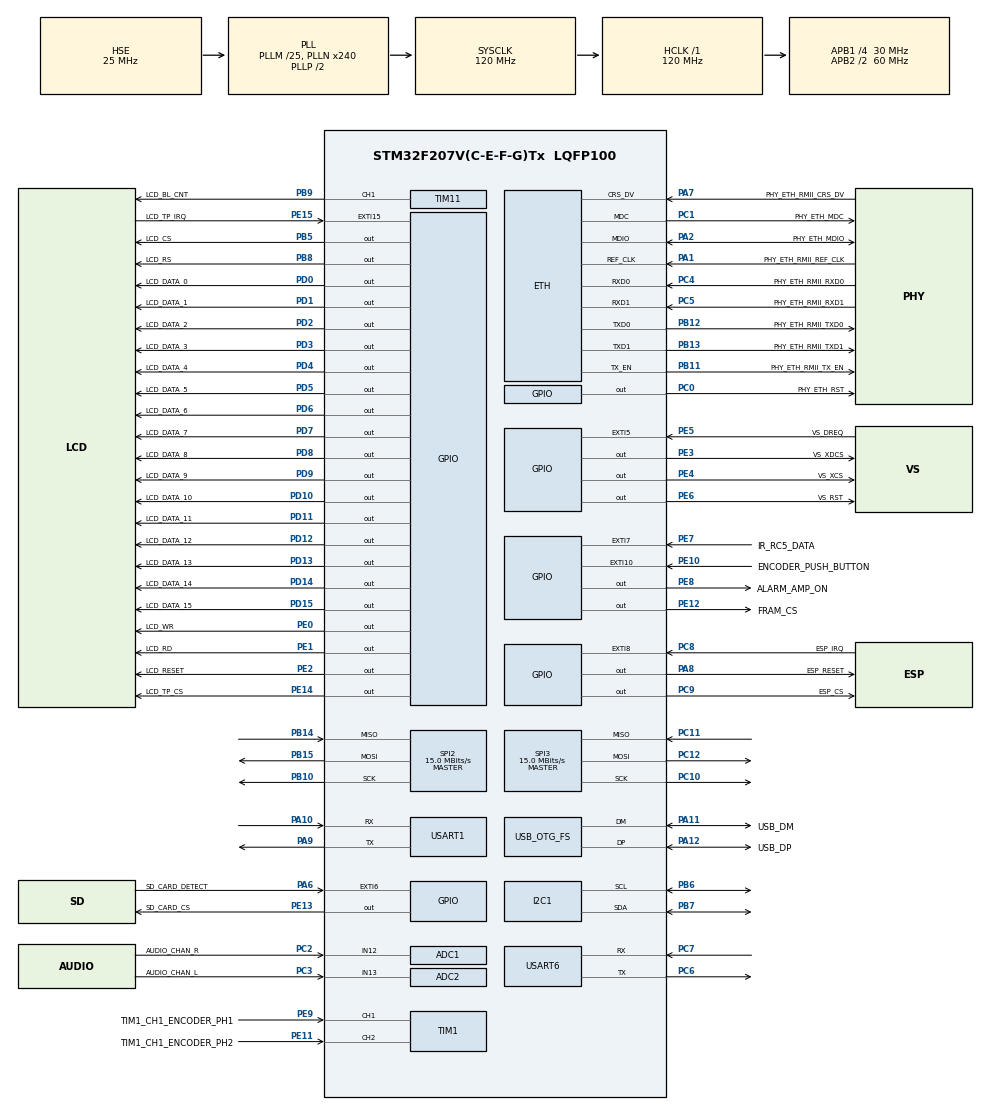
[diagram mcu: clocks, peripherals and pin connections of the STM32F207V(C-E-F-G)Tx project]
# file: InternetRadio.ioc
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ADC1.Channel-0\#ChannelRegularConversion=ADC_CHANNEL_12
ADC1.ClockPrescaler=ADC_CLOCK_SYNC_PCLK_DIV4
ADC1.NbrOfConversionFlag=1
ADC1.Rank-0\#ChannelRegularConversion=1
ADC1.SamplingTime-0\#ChannelRegularConversion=ADC_SAMPLETIME_3CYCLES
ADC1.master=1
ADC2.Channel-0\#ChannelRegularConversion=ADC_CHANNEL_13
ADC2.ClockPrescaler=ADC_CLOCK_SYNC_PCLK_DIV4
ADC2.NbrOfConversionFlag=1
ADC2.Rank-0\#ChannelRegularConversion=1
ADC2.SamplingTime-0\#ChannelRegularConversion=ADC_SAMPLETIME_3CYCLES
ETH.MediaInterface=ETH_MEDIA_INTERFACE_RMII
ETH.PHY_Name_RMII=DP83848_PHY_ADDRESS
FATFS._USE_FIND=1
FREERTOS.Tasks01=defaultTask,24,128,StartDefaultTask,Default,NULL,Dynamic,NULL,NULL
FREERTOS.configUSE_NEWLIB_REENTRANT=1
LWIP.Version=v2.0.3_Cube
Mcu.Family=STM32F2
Mcu.Name=STM32F207V(C-E-F-G)Tx
Mcu.Package=LQFP100
NVIC.ETH_IRQn=true\:5\:0\:false\:false\:true\:true\:false\:true
NVIC.PriorityGroup=NVIC_PRIORITYGROUP_4
PA0-WKUP.GPIO_Label=PHY_ETH_INT
PA0-WKUP.Mode=SYS_WakeUp0
PA0-WKUP.Signal=SYS_WKUP
PA1.GPIO_Label=PHY_ETH_RMII_REF_CLK
PA1.Mode=RMII
PA1.Signal=ETH_REF_CLK
PA10.Mode=Asynchronous
PA10.Signal=USART1_RX
PA11.GPIO_Label=USB_DM
PA11.Mode=Device_Only
PA11.Signal=USB_OTG_FS_DM
PA12.GPIO_Label=USB_DP
PA12.Mode=Device_Only
PA12.Signal=USB_OTG_FS_DP
PA13.GPIO_Label=JTMS
PA13.Mode=JTAG_5_pins
PA13.Signal=SYS_JTMS-SWDIO
PA14.GPIO_Label=JTCK
PA14.Mode=JTAG_5_pins
PA14.Signal=SYS_JTCK-SWCLK
PA15.GPIO_Label=JTDI
PA15.Mode=JTAG_5_pins
PA15.Signal=SYS_JTDI
PA2.GPIO_Label=PHY_ETH_MDIO
PA2.Mode=RMII
PA2.Signal=ETH_MDIO
PA6.GPIO_Label=SD_CARD_DETECT
PA6.Signal=GPXTI6
PA7.GPIO_Label=PHY_ETH_RMII_CRS_DV
PA7.Mode=RMII
PA7.Signal=ETH_CRS_DV
PA8.GPIO_Label=ESP_RESET
PA8.Signal=GPIO_Output
PA9.Mode=Asynchronous
PA9.Signal=USART1_TX
PB10.Mode=Full_Duplex_Master
PB10.Signal=SPI2_SCK
PB11.GPIO_Label=PHY_ETH_RMII_TX_EN
PB11.Mode=RMII
PB11.Signal=ETH_TX_EN
PB12.GPIO_Label=PHY_ETH_RMII_TXD0
PB12.Mode=RMII
PB12.Signal=ETH_TXD0
PB13.GPIO_Label=PHY_ETH_RMII_TXD1
PB13.Mode=RMII
PB13.Signal=ETH_TXD1
PB14.Mode=Full_Duplex_Master
PB14.Signal=SPI2_MISO
PB15.Mode=Full_Duplex_Master
PB15.Signal=SPI2_MOSI
PB3.GPIO_Label=JTDO
PB3.Mode=JTAG_5_pins
PB3.Signal=SYS_JTDO-SWO
PB4.GPIO_Label=JTRST
PB4.Mode=JTAG_5_pins
PB4.Signal=SYS_JTRST
PB5.GPIO_Label=LCD_CS
PB5.Signal=GPIO_Output
PB6.Mode=I2C
PB6.Signal=I2C1_SCL
PB7.Mode=I2C
PB7.Signal=I2C1_SDA
PB8.GPIO_Label=LCD_RS
PB8.Signal=GPIO_Output
PB9.GPIO_Label=LCD_BL_CNT
PB9.Signal=S_TIM11_CH1
PC0.GPIO_Label=PHY_ETH_RST
PC0.Signal=GPIO_Output
PC1.GPIO_Label=PHY_ETH_MDC
PC1.Mode=RMII
PC1.Signal=ETH_MDC
PC10.Mode=Full_Duplex_Master
PC10.Signal=SPI3_SCK
PC11.Mode=Full_Duplex_Master
PC11.Signal=SPI3_MISO
PC12.Mode=Full_Duplex_Master
PC12.Signal=SPI3_MOSI
PC14-OSC32_IN.Mode=LSE-External-Oscillator
PC14-OSC32_IN.Signal=RCC_OSC32_IN
PC15-OSC32_OUT.Mode=LSE-External-Oscillator
PC15-OSC32_OUT.Signal=RCC_OSC32_OUT
PC2.GPIO_Label=AUDIO_CHAN_R
PC2.Signal=ADCx_IN12
PC3.GPIO_Label=AUDIO_CHAN_L
PC3.Signal=ADCx_IN13
PC4.GPIO_Label=PHY_ETH_RMII_RXD0
PC4.Mode=RMII
PC4.Signal=ETH_RXD0
PC5.GPIO_Label=PHY_ETH_RMII_RXD1
PC5.Mode=RMII
PC5.Signal=ETH_RXD1
PC6.Mode=Asynchronous
PC6.Signal=USART6_TX
PC7.Mode=Asynchronous
PC7.Signal=USART6_RX
PC8.GPIO_Label=ESP_IRQ
PC8.Signal=GPXTI8
PC9.GPIO_Label=ESP_CS
PC9.Signal=GPIO_Output
PD0.GPIO_Label=LCD_DATA_0
PD0.Signal=GPIO_Output
PD1.GPIO_Label=LCD_DATA_1
PD1.Signal=GPIO_Output
PD10.GPIO_Label=LCD_DATA_10
PD10.Signal=GPIO_Output
PD11.GPIO_Label=LCD_DATA_11
PD11.Signal=GPIO_Output
PD12.GPIO_Label=LCD_DATA_12
PD12.Signal=GPIO_Output
PD13.GPIO_Label=LCD_DATA_13
PD13.Signal=GPIO_Output
PD14.GPIO_Label=LCD_DATA_14
PD14.Signal=GPIO_Output
PD15.GPIO_Label=LCD_DATA_15
PD15.Signal=GPIO_Output
PD2.GPIO_Label=LCD_DATA_2
PD2.Signal=GPIO_Output
PD3.GPIO_Label=LCD_DATA_3
PD3.Signal=GPIO_Output
PD4.GPIO_Label=LCD_DATA_4
PD4.Signal=GPIO_Output
PD5.GPIO_Label=LCD_DATA_5
PD5.Signal=GPIO_Output
PD6.GPIO_Label=LCD_DATA_6
PD6.Signal=GPIO_Output
PD7.GPIO_Label=LCD_DATA_7
PD7.Signal=GPIO_Output
PD8.GPIO_Label=LCD_DATA_8
PD8.Signal=GPIO_Output
PD9.GPIO_Label=LCD_DATA_9
PD9.Signal=GPIO_Output
PE0.GPIO_Label=LCD_WR
PE0.Signal=GPIO_Output
PE1.GPIO_Label=LCD_RD
PE1.Signal=GPIO_Output
PE10.GPIO_Label=ENCODER_PUSH_BUTTON
PE10.Signal=GPXTI10
PE11.GPIO_Label=TIM1_CH1_ENCODER_PH2
PE11.Signal=S_TIM1_CH2
PE12.GPIO_Label=FRAM_CS
PE12.Signal=GPIO_Output
PE13.GPIO_Label=SD_CARD_CS
PE13.Signal=GPIO_Output
PE14.GPIO_Label=LCD_TP_CS
PE14.Signal=GPIO_Output
PE15.GPIO_Label=LCD_TP_IRQ
PE15.Signal=GPXTI15
PE2.GPIO_Label=LCD_RESET
PE2.Signal=GPIO_Output
PE3.GPIO_Label=VS_XDCS
PE3.Signal=GPIO_Output
PE4.GPIO_Label=VS_XCS
PE4.Signal=GPIO_Output
PE5.GPIO_Label=VS_DREQ
PE5.Signal=GPXTI5
PE6.GPIO_Label=VS_RST
PE6.Signal=GPIO_Output
PE7.GPIO_Label=IR_RC5_DATA
PE7.Signal=GPXTI7
PE8.GPIO_Label=ALARM_AMP_ON
PE8.Signal=GPIO_Output
PE9.GPIO_Label=TIM1_CH1_ENCODER_PH1
PE9.Signal=S_TIM1_CH1
PH0-OSC_IN.Mode=HSE-External-Oscillator
PH0-OSC_IN.Signal=RCC_OSC_IN
PH1-OSC_OUT.Mode=HSE-External-Oscillator
PH1-OSC_OUT.Signal=RCC_OSC_OUT
ProjectManager.HeapSize=0x200
ProjectManager.StackSize=0x400
ProjectManager.TargetToolchain=STM32CubeIDE
RCC.48MHZClocksFreq_Value=48000000
RCC.AHBFreq_Value=120000000
RCC.APB1CLKDivider=RCC_HCLK_DIV4
RCC.APB1Freq_Value=30000000
RCC.APB1TimFreq_Value=60000000
RCC.APB2CLKDivider=RCC_HCLK_DIV2
RCC.APB2Freq_Value=60000000
RCC.APB2TimFreq_Value=120000000
RCC.CortexFreq_Value=120000000
RCC.HCLKFreq_Value=120000000
RCC.HSE_VALUE=25000000
RCC.HSI_VALUE=16000000
RCC.PLLM=25
RCC.PLLN=240
RCC.PLLQ=5
RCC.PLLSourceVirtual=RCC_PLLSOURCE_HSE
RCC.RCC_RTC_Clock_Source=RCC_RTCCLKSOURCE_LSE
RCC.RCC_RTC_Clock_SourceVirtual=RCC_RTCCLKSOURCE_LSE
RCC.SYSCLKFreq_VALUE=120000000
RCC.SYSCLKSource=RCC_SYSCLKSOURCE_PLLCLK
RCC.VCOOutputFreq_Value=240000000
SH.ADCx_IN12.0=ADC1_IN12,IN12
SH.ADCx_IN13.0=ADC2_IN13,IN13
SH.S_TIM11_CH1.0=TIM11_CH1,PWM Generation1 CH1
SH.S_TIM1_CH1.0=TIM1_CH1,Encoder_Interface
SH.S_TIM1_CH2.0=TIM1_CH2,Encoder_Interface
SPI2.BaudRatePrescaler=SPI_BAUDRATEPRESCALER_2
SPI2.CalculateBaudRate=15.0 MBits/s
SPI2.Direction=SPI_DIRECTION_2LINES
SPI2.Mode=SPI_MODE_MASTER
SPI2.VirtualType=VM_MASTER
SPI3.BaudRatePrescaler=SPI_BAUDRATEPRESCALER_2
SPI3.CalculateBaudRate=15.0 MBits/s
SPI3.Direction=SPI_DIRECTION_2LINES
SPI3.Mode=SPI_MODE_MASTER
SPI3.VirtualType=VM_MASTER
TIM11.Channel=TIM_CHANNEL_1
TIM11.Period=0x0064
TIM11.Prescaler=0x0075
TIM7.Prescaler=0x001D
USART1.VirtualMode=VM_ASYNC
USART6.VirtualMode=VM_ASYNC
USB_OTG_FS.VirtualMode=Device_Only
VP_FATFS_VS_Generic.Mode=User_defined
VP_FREERTOS_VS_CMSIS_V2.Mode=CMSIS_V2
VP_LWIP_VS_Enabled.Mode=Enabled
VP_RTC_VS_RTC_Activate.Mode=RTC_Enabled
VP_RTC_VS_RTC_Calendar.Mode=RTC_Calendar
VP_TIM11_VS_ClockSourceINT.Mode=Enable_Timer
VP_TIM7_VS_ClockSourceINT.Mode=Enable_Timer
board=custom

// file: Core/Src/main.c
/* USER CODE BEGIN Header */
/**
  ******************************************************************************
  * @file           : main.c
  * @brief          : Main program body
  ******************************************************************************
  * @attention
  *
  * Copyright (c) 2021 STMicroelectronics.
  * All rights reserved.
  *
  * This software is licensed under terms that can be found in the LICENSE file
  * in the root directory of this software component.
  * If no LICENSE file comes with this software, it is provided AS-IS.
  *
  ******************************************************************************
  */
/* USER CODE END Header */
#include "main.h"
#include "cmsis_os.h"
#include "fatfs.h"
#include "lwip.h"

ADC_HandleTypeDef hadc1;
ADC_HandleTypeDef hadc2;

I2C_HandleTypeDef hi2c1;

RTC_HandleTypeDef hrtc;

SPI_HandleTypeDef hspi2;
SPI_HandleTypeDef hspi3;

TIM_HandleTypeDef htim1;
TIM_HandleTypeDef htim7;
TIM_HandleTypeDef htim11;

UART_HandleTypeDef huart1;
UART_HandleTypeDef huart6;

PCD_HandleTypeDef hpcd_USB_OTG_FS;

/* Definitions for defaultTask */
osThreadId_t defaultTaskHandle;
const osThreadAttr_t defaultTask_attributes = {
  .name = "defaultTask",
  .stack_size = 128 * 4,
  .priority = (osPriority_t) osPriorityNormal,
};
/* USER CODE BEGIN PV */
osThreadId_t LED_HB_Task_handle;
const osThreadAttr_t LED_HB_Task_attributes = {
  .name = "LED_HB_Task",
  .stack_size = 128 * 4,
  .priority = (osPriority_t) osPriorityNormal,
};
/* USER CODE END PV */

void SystemClock_Config(void);
static void MX_GPIO_Init(void);
static void MX_ADC1_Init(void);
static void MX_ADC2_Init(void);
static void MX_I2C1_Init(void);
static void MX_SPI2_Init(void);
static void MX_SPI3_Init(void);
static void MX_TIM1_Init(void);
static void MX_USART1_UART_Init(void);
static void MX_USART6_UART_Init(void);
static void MX_USB_OTG_FS_PCD_Init(void);
static void MX_RTC_Init(void);
static void MX_TIM7_Init(void);
static void MX_TIM11_Init(void);
void StartDefaultTask(void *argument);

/* USER CODE BEGIN PFP */
void LED_HB_Task(void *argument);
/* USER CODE END PFP */

int main(void)
{

  /* MCU Configuration--------------------------------------------------------*/

  /* Reset of all peripherals, Initializes the Flash interface and the Systick. */
  HAL_Init();

  /* Configure the system clock */
  SystemClock_Config();

  /* Initialize all configured peripherals */
  MX_GPIO_Init();
  MX_ADC1_Init();
  MX_ADC2_Init();
  MX_I2C1_Init();
  MX_SPI2_Init();
  MX_SPI3_Init();
  MX_TIM1_Init();
  MX_USART1_UART_Init();
  MX_USART6_UART_Init();
  MX_USB_OTG_FS_PCD_Init();
  MX_FATFS_Init();
  MX_RTC_Init();
  MX_TIM7_Init();
  MX_TIM11_Init();

  /* Init scheduler */
  osKernelInitialize();

  /* Create the thread(s) */
  /* creation of defaultTask */
  defaultTaskHandle = osThreadNew(StartDefaultTask, NULL, &defaultTask_attributes);

  /* USER CODE BEGIN RTOS_THREADS */
  LED_HB_Task_handle = osThreadNew(LED_HB_Task, NULL, &LED_HB_Task_attributes);
  /* add threads, ... */
  /* USER CODE END RTOS_THREADS */

  /* Start scheduler */
  osKernelStart();

  /* We should never get here as control is now taken by the scheduler */
  /* Infinite loop */
  while (1)
  {

  }
}

void SystemClock_Config(void)
{
  RCC_OscInitTypeDef RCC_OscInitStruct = {0};
  RCC_ClkInitTypeDef RCC_ClkInitStruct = {0};
  RCC_PeriphCLKInitTypeDef PeriphClkInitStruct = {0};

  /** Initializes the RCC Oscillators according to the specified parameters
  * in the RCC_OscInitTypeDef structure.
  */
  RCC_OscInitStruct.OscillatorType = RCC_OSCILLATORTYPE_HSE|RCC_OSCILLATORTYPE_LSE;
  RCC_OscInitStruct.HSEState = RCC_HSE_ON;
  RCC_OscInitStruct.LSEState = RCC_LSE_ON;
  RCC_OscInitStruct.PLL.PLLState = RCC_PLL_ON;
  RCC_OscInitStruct.PLL.PLLSource = RCC_PLLSOURCE_HSE;
  RCC_OscInitStruct.PLL.PLLM = 25;
  RCC_OscInitStruct.PLL.PLLN = 240;
  RCC_OscInitStruct.PLL.PLLP = RCC_PLLP_DIV2;
  RCC_OscInitStruct.PLL.PLLQ = 5;
  if (HAL_RCC_OscConfig(&RCC_OscInitStruct) != HAL_OK)
  {
    Error_Handler();
  }
  /** Initializes the CPU, AHB and APB buses clocks
  */
  RCC_ClkInitStruct.ClockType = RCC_CLOCKTYPE_HCLK|RCC_CLOCKTYPE_SYSCLK
                              |RCC_CLOCKTYPE_PCLK1|RCC_CLOCKTYPE_PCLK2;
  RCC_ClkInitStruct.SYSCLKSource = RCC_SYSCLKSOURCE_PLLCLK;
  RCC_ClkInitStruct.AHBCLKDivider = RCC_SYSCLK_DIV1;
  RCC_ClkInitStruct.APB1CLKDivider = RCC_HCLK_DIV4;
  RCC_ClkInitStruct.APB2CLKDivider = RCC_HCLK_DIV2;

  if (HAL_RCC_ClockConfig(&RCC_ClkInitStruct, FLASH_LATENCY_3) != HAL_OK)
  {
    Error_Handler();
  }
  PeriphClkInitStruct.PeriphClockSelection = RCC_PERIPHCLK_RTC;
  PeriphClkInitStruct.RTCClockSelection = RCC_RTCCLKSOURCE_LSE;
  if (HAL_RCCEx_PeriphCLKConfig(&PeriphClkInitStruct) != HAL_OK)
  {
    Error_Handler();
  }
}

static void MX_ADC1_Init(void)
{

  ADC_ChannelConfTypeDef sConfig = {0};

  /** Configure the global features of the ADC (Clock, Resolution, Data Alignment and number of conversion)
  */
  hadc1.Instance = ADC1;
  hadc1.Init.ClockPrescaler = ADC_CLOCK_SYNC_PCLK_DIV4;
  hadc1.Init.Resolution = ADC_RESOLUTION_12B;
  hadc1.Init.ScanConvMode = DISABLE;
  hadc1.Init.ContinuousConvMode = DISABLE;
  hadc1.Init.DiscontinuousConvMode = DISABLE;
  hadc1.Init.ExternalTrigConvEdge = ADC_EXTERNALTRIGCONVEDGE_NONE;
  hadc1.Init.ExternalTrigConv = ADC_SOFTWARE_START;
  hadc1.Init.DataAlign = ADC_DATAALIGN_RIGHT;
  hadc1.Init.NbrOfConversion = 1;
  hadc1.Init.DMAContinuousRequests = DISABLE;
  hadc1.Init.EOCSelection = ADC_EOC_SINGLE_CONV;
  if (HAL_ADC_Init(&hadc1) != HAL_OK)
  {
    Error_Handler();
  }
  /** Configure for the selected ADC regular channel its corresponding rank in the sequencer and its sample time.
  */
  sConfig.Channel = ADC_CHANNEL_12;
  sConfig.Rank = 1;
  sConfig.SamplingTime = ADC_SAMPLETIME_3CYCLES;
  if (HAL_ADC_ConfigChannel(&hadc1, &sConfig) != HAL_OK)
  {
    Error_Handler();
  }

}

static void MX_ADC2_Init(void)
{

  ADC_ChannelConfTypeDef sConfig = {0};

  /** Configure the global features of the ADC (Clock, Resolution, Data Alignment and number of conversion)
  */
  hadc2.Instance = ADC2;
  hadc2.Init.ClockPrescaler = ADC_CLOCK_SYNC_PCLK_DIV4;
  hadc2.Init.Resolution = ADC_RESOLUTION_12B;
  hadc2.Init.ScanConvMode = DISABLE;
  hadc2.Init.ContinuousConvMode = DISABLE;
  hadc2.Init.DiscontinuousConvMode = DISABLE;
  hadc2.Init.ExternalTrigConvEdge = ADC_EXTERNALTRIGCONVEDGE_NONE;
  hadc2.Init.ExternalTrigConv = ADC_SOFTWARE_START;
  hadc2.Init.DataAlign = ADC_DATAALIGN_RIGHT;
  hadc2.Init.NbrOfConversion = 1;
  hadc2.Init.DMAContinuousRequests = DISABLE;
  hadc2.Init.EOCSelection = ADC_EOC_SINGLE_CONV;
  if (HAL_ADC_Init(&hadc2) != HAL_OK)
  {
    Error_Handler();
  }
  /** Configure for the selected ADC regular channel its corresponding rank in the sequencer and its sample time.
  */
  sConfig.Channel = ADC_CHANNEL_13;
  sConfig.Rank = 1;
  sConfig.SamplingTime = ADC_SAMPLETIME_3CYCLES;
  if (HAL_ADC_ConfigChannel(&hadc2, &sConfig) != HAL_OK)
  {
    Error_Handler();
  }

}

static void MX_I2C1_Init(void)
{

  hi2c1.Instance = I2C1;
  hi2c1.Init.ClockSpeed = 100000;
  hi2c1.Init.DutyCycle = I2C_DUTYCYCLE_2;
  hi2c1.Init.OwnAddress1 = 0;
  hi2c1.Init.AddressingMode = I2C_ADDRESSINGMODE_7BIT;
  hi2c1.Init.DualAddressMode = I2C_DUALADDRESS_DISABLE;
  hi2c1.Init.OwnAddress2 = 0;
  hi2c1.Init.GeneralCallMode = I2C_GENERALCALL_DISABLE;
  hi2c1.Init.NoStretchMode = I2C_NOSTRETCH_DISABLE;
  if (HAL_I2C_Init(&hi2c1) != HAL_OK)
  {
    Error_Handler();
  }

}

static void MX_RTC_Init(void)
{

  RTC_TimeTypeDef sTime = {0};
  RTC_DateTypeDef sDate = {0};

  /** Initialize RTC Only
  */
  hrtc.Instance = RTC;
  hrtc.Init.HourFormat = RTC_HOURFORMAT_24;
  hrtc.Init.AsynchPrediv = 127;
  hrtc.Init.SynchPrediv = 255;
  hrtc.Init.OutPut = RTC_OUTPUT_DISABLE;
  hrtc.Init.OutPutPolarity = RTC_OUTPUT_POLARITY_HIGH;
  hrtc.Init.OutPutType = RTC_OUTPUT_TYPE_OPENDRAIN;
  if (HAL_RTC_Init(&hrtc) != HAL_OK)
  {
    Error_Handler();
  }

  /** Initialize RTC and set the Time and Date
  */
  sTime.Hours = 0x0;
  sTime.Minutes = 0x0;
  sTime.Seconds = 0x0;
  sTime.DayLightSaving = RTC_DAYLIGHTSAVING_NONE;
  sTime.StoreOperation = RTC_STOREOPERATION_RESET;
  if (HAL_RTC_SetTime(&hrtc, &sTime, RTC_FORMAT_BCD) != HAL_OK)
  {
    Error_Handler();
  }
  sDate.WeekDay = RTC_WEEKDAY_MONDAY;
  sDate.Month = RTC_MONTH_JANUARY;
  sDate.Date = 0x1;
  sDate.Year = 0x0;

  if (HAL_RTC_SetDate(&hrtc, &sDate, RTC_FORMAT_BCD) != HAL_OK)
  {
    Error_Handler();
  }

}

static void MX_SPI2_Init(void)
{

  /* SPI2 parameter configuration*/
  hspi2.Instance = SPI2;
  hspi2.Init.Mode = SPI_MODE_MASTER;
  hspi2.Init.Direction = SPI_DIRECTION_2LINES;
  hspi2.Init.DataSize = SPI_DATASIZE_8BIT;
  hspi2.Init.CLKPolarity = SPI_POLARITY_LOW;
  hspi2.Init.CLKPhase = SPI_PHASE_1EDGE;
  hspi2.Init.NSS = SPI_NSS_SOFT;
  hspi2.Init.BaudRatePrescaler = SPI_BAUDRATEPRESCALER_2;
  hspi2.Init.FirstBit = SPI_FIRSTBIT_MSB;
  hspi2.Init.TIMode = SPI_TIMODE_DISABLE;
  hspi2.Init.CRCCalculation = SPI_CRCCALCULATION_DISABLE;
  hspi2.Init.CRCPolynomial = 10;
  if (HAL_SPI_Init(&hspi2) != HAL_OK)
  {
    Error_Handler();
  }

}

static void MX_SPI3_Init(void)
{

  /* SPI3 parameter configuration*/
  hspi3.Instance = SPI3;
  hspi3.Init.Mode = SPI_MODE_MASTER;
  hspi3.Init.Direction = SPI_DIRECTION_2LINES;
  hspi3.Init.DataSize = SPI_DATASIZE_8BIT;
  hspi3.Init.CLKPolarity = SPI_POLARITY_LOW;
  hspi3.Init.CLKPhase = SPI_PHASE_1EDGE;
  hspi3.Init.NSS = SPI_NSS_SOFT;
  hspi3.Init.BaudRatePrescaler = SPI_BAUDRATEPRESCALER_2;
  hspi3.Init.FirstBit = SPI_FIRSTBIT_MSB;
  hspi3.Init.TIMode = SPI_TIMODE_DISABLE;
  hspi3.Init.CRCCalculation = SPI_CRCCALCULATION_DISABLE;
  hspi3.Init.CRCPolynomial = 10;
  if (HAL_SPI_Init(&hspi3) != HAL_OK)
  {
    Error_Handler();
  }

}

static void MX_TIM1_Init(void)
{

  TIM_Encoder_InitTypeDef sConfig = {0};
  TIM_MasterConfigTypeDef sMasterConfig = {0};

  htim1.Instance = TIM1;
  htim1.Init.Prescaler = 0;
  htim1.Init.CounterMode = TIM_COUNTERMODE_UP;
  htim1.Init.Period = 65535;
  htim1.Init.ClockDivision = TIM_CLOCKDIVISION_DIV1;
  htim1.Init.RepetitionCounter = 0;
  htim1.Init.AutoReloadPreload = TIM_AUTORELOAD_PRELOAD_DISABLE;
  sConfig.EncoderMode = TIM_ENCODERMODE_TI1;
  sConfig.IC1Polarity = TIM_ICPOLARITY_RISING;
  sConfig.IC1Selection = TIM_ICSELECTION_DIRECTTI;
  sConfig.IC1Prescaler = TIM_ICPSC_DIV1;
  sConfig.IC1Filter = 0;
  sConfig.IC2Polarity = TIM_ICPOLARITY_RISING;
  sConfig.IC2Selection = TIM_ICSELECTION_DIRECTTI;
  sConfig.IC2Prescaler = TIM_ICPSC_DIV1;
  sConfig.IC2Filter = 0;
  if (HAL_TIM_Encoder_Init(&htim1, &sConfig) != HAL_OK)
  {
    Error_Handler();
  }
  sMasterConfig.MasterOutputTrigger = TIM_TRGO_RESET;
  sMasterConfig.MasterSlaveMode = TIM_MASTERSLAVEMODE_DISABLE;
  if (HAL_TIMEx_MasterConfigSynchronization(&htim1, &sMasterConfig) != HAL_OK)
  {
    Error_Handler();
  }

}

static void MX_TIM7_Init(void)
{

  TIM_MasterConfigTypeDef sMasterConfig = {0};

  htim7.Instance = TIM7;
  htim7.Init.Prescaler = 0x001D;
  htim7.Init.CounterMode = TIM_COUNTERMODE_UP;
  htim7.Init.Period = 65535;
  htim7.Init.AutoReloadPreload = TIM_AUTORELOAD_PRELOAD_DISABLE;
  if (HAL_TIM_Base_Init(&htim7) != HAL_OK)
  {
    Error_Handler();
  }
  sMasterConfig.MasterOutputTrigger = TIM_TRGO_RESET;
  sMasterConfig.MasterSlaveMode = TIM_MASTERSLAVEMODE_DISABLE;
  if (HAL_TIMEx_MasterConfigSynchronization(&htim7, &sMasterConfig) != HAL_OK)
  {
    Error_Handler();
  }

}

static void MX_TIM11_Init(void)
{

  TIM_OC_InitTypeDef sConfigOC = {0};

  htim11.Instance = TIM11;
  htim11.Init.Prescaler = 0x0075;
  htim11.Init.CounterMode = TIM_COUNTERMODE_UP;
  htim11.Init.Period = 0x0064;
  htim11.Init.ClockDivision = TIM_CLOCKDIVISION_DIV1;
  htim11.Init.AutoReloadPreload = TIM_AUTORELOAD_PRELOAD_DISABLE;
  if (HAL_TIM_Base_Init(&htim11) != HAL_OK)
  {
    Error_Handler();
  }
  if (HAL_TIM_PWM_Init(&htim11) != HAL_OK)
  {
    Error_Handler();
  }
  sConfigOC.OCMode = TIM_OCMODE_PWM1;
  sConfigOC.Pulse = 0;
  sConfigOC.OCPolarity = TIM_OCPOLARITY_HIGH;
  sConfigOC.OCFastMode = TIM_OCFAST_DISABLE;
  if (HAL_TIM_PWM_ConfigChannel(&htim11, &sConfigOC, TIM_CHANNEL_1) != HAL_OK)
  {
    Error_Handler();
  }
  HAL_TIM_MspPostInit(&htim11);

}

static void MX_USART1_UART_Init(void)
{

  huart1.Instance = USART1;
  huart1.Init.BaudRate = 115200;
  huart1.Init.WordLength = UART_WORDLENGTH_8B;
  huart1.Init.StopBits = UART_STOPBITS_1;
  huart1.Init.Parity = UART_PARITY_NONE;
  huart1.Init.Mode = UART_MODE_TX_RX;
  huart1.Init.HwFlowCtl = UART_HWCONTROL_NONE;
  huart1.Init.OverSampling = UART_OVERSAMPLING_16;
  if (HAL_UART_Init(&huart1) != HAL_OK)
  {
    Error_Handler();
  }

}

static void MX_USART6_UART_Init(void)
{

  huart6.Instance = USART6;
  huart6.Init.BaudRate = 115200;
  huart6.Init.WordLength = UART_WORDLENGTH_8B;
  huart6.Init.StopBits = UART_STOPBITS_1;
  huart6.Init.Parity = UART_PARITY_NONE;
  huart6.Init.Mode = UART_MODE_TX_RX;
  huart6.Init.HwFlowCtl = UART_HWCONTROL_NONE;
  huart6.Init.OverSampling = UART_OVERSAMPLING_16;
  if (HAL_UART_Init(&huart6) != HAL_OK)
  {
    Error_Handler();
  }

}

static void MX_USB_OTG_FS_PCD_Init(void)
{

  hpcd_USB_OTG_FS.Instance = USB_OTG_FS;
  hpcd_USB_OTG_FS.Init.dev_endpoints = 4;
  hpcd_USB_OTG_FS.Init.speed = PCD_SPEED_FULL;
  hpcd_USB_OTG_FS.Init.dma_enable = DISABLE;
  hpcd_USB_OTG_FS.Init.phy_itface = PCD_PHY_EMBEDDED;
  hpcd_USB_OTG_FS.Init.Sof_enable = DISABLE;
  hpcd_USB_OTG_FS.Init.low_power_enable = DISABLE;
  hpcd_USB_OTG_FS.Init.vbus_sensing_enable = DISABLE;
  hpcd_USB_OTG_FS.Init.use_dedicated_ep1 = DISABLE;
  if (HAL_PCD_Init(&hpcd_USB_OTG_FS) != HAL_OK)
  {
    Error_Handler();
  }

}

static void MX_GPIO_Init(void)
{
  GPIO_InitTypeDef GPIO_InitStruct = {0};

  /* GPIO Ports Clock Enable */
  __HAL_RCC_GPIOE_CLK_ENABLE();
  __HAL_RCC_GPIOC_CLK_ENABLE();
  __HAL_RCC_GPIOH_CLK_ENABLE();
  __HAL_RCC_GPIOA_CLK_ENABLE();
  __HAL_RCC_GPIOB_CLK_ENABLE();
  __HAL_RCC_GPIOD_CLK_ENABLE();

  /*Configure GPIO pin Output Level */
  HAL_GPIO_WritePin(GPIOE, LCD_RESET_Pin|VS_XDCS_Pin|VS_XCS_Pin|VS_RST_Pin
                          |ALARM_AMP_ON_Pin|FRAM_CS_Pin|SD_CARD_CS_Pin|LCD_TP_CS_Pin
                          |LCD_WR_Pin|LCD_RD_Pin, GPIO_PIN_RESET);

  /*Configure GPIO pin Output Level */
  HAL_GPIO_WritePin(GPIOC, PHY_ETH_RST_Pin|ESP_CS_Pin, GPIO_PIN_RESET);

  /*Configure GPIO pin Output Level */
  HAL_GPIO_WritePin(GPIOD, LCD_DATA_8_Pin|LCD_DATA_9_Pin|LCD_DATA_10_Pin|LCD_DATA_11_Pin
                          |LCD_DATA_12_Pin|LCD_DATA_13_Pin|LCD_DATA_14_Pin|LCD_DATA_15_Pin
                          |LCD_DATA_0_Pin|LCD_DATA_1_Pin|LCD_DATA_2_Pin|LCD_DATA_3_Pin
                          |LCD_DATA_4_Pin|LCD_DATA_5_Pin|LCD_DATA_6_Pin|LCD_DATA_7_Pin, GPIO_PIN_RESET);

  /*Configure GPIO pin Output Level */
  HAL_GPIO_WritePin(ESP_RESET_GPIO_Port, ESP_RESET_Pin, GPIO_PIN_RESET);

  /*Configure GPIO pin Output Level */
  HAL_GPIO_WritePin(GPIOB, LCD_CS_Pin|LCD_RS_Pin, GPIO_PIN_RESET);

  /*Configure GPIO pins : LCD_RESET_Pin VS_XDCS_Pin VS_XCS_Pin VS_RST_Pin
                           ALARM_AMP_ON_Pin FRAM_CS_Pin SD_CARD_CS_Pin LCD_TP_CS_Pin
                           LCD_WR_Pin LCD_RD_Pin */
  GPIO_InitStruct.Pin = LCD_RESET_Pin|VS_XDCS_Pin|VS_XCS_Pin|VS_RST_Pin
                          |ALARM_AMP_ON_Pin|FRAM_CS_Pin|SD_CARD_CS_Pin|LCD_TP_CS_Pin
                          |LCD_WR_Pin|LCD_RD_Pin;
  GPIO_InitStruct.Mode = GPIO_MODE_OUTPUT_PP;
  GPIO_InitStruct.Pull = GPIO_NOPULL;
  GPIO_InitStruct.Speed = GPIO_SPEED_FREQ_LOW;
  HAL_GPIO_Init(GPIOE, &GPIO_InitStruct);

  /*Configure GPIO pins : VS_DREQ_Pin IR_RC5_DATA_Pin ENCODER_PUSH_BUTTON_Pin LCD_TP_IRQ_Pin */
  GPIO_InitStruct.Pin = VS_DREQ_Pin|IR_RC5_DATA_Pin|ENCODER_PUSH_BUTTON_Pin|LCD_TP_IRQ_Pin;
  GPIO_InitStruct.Mode = GPIO_MODE_IT_RISING;
  GPIO_InitStruct.Pull = GPIO_NOPULL;
  HAL_GPIO_Init(GPIOE, &GPIO_InitStruct);

  /*Configure GPIO pins : PHY_ETH_RST_Pin ESP_CS_Pin */
  GPIO_InitStruct.Pin = PHY_ETH_RST_Pin|ESP_CS_Pin;
  GPIO_InitStruct.Mode = GPIO_MODE_OUTPUT_PP;
  GPIO_InitStruct.Pull = GPIO_NOPULL;
  GPIO_InitStruct.Speed = GPIO_SPEED_FREQ_LOW;
  HAL_GPIO_Init(GPIOC, &GPIO_InitStruct);

  /*Configure GPIO pin : SD_CARD_DETECT_Pin */
  GPIO_InitStruct.Pin = SD_CARD_DETECT_Pin;
  GPIO_InitStruct.Mode = GPIO_MODE_IT_RISING;
  GPIO_InitStruct.Pull = GPIO_NOPULL;
  HAL_GPIO_Init(SD_CARD_DETECT_GPIO_Port, &GPIO_InitStruct);

  /*Configure GPIO pins : LCD_DATA_8_Pin LCD_DATA_9_Pin LCD_DATA_10_Pin LCD_DATA_11_Pin
                           LCD_DATA_12_Pin LCD_DATA_13_Pin LCD_DATA_14_Pin LCD_DATA_15_Pin
                           LCD_DATA_0_Pin LCD_DATA_1_Pin LCD_DATA_2_Pin LCD_DATA_3_Pin
                           LCD_DATA_4_Pin LCD_DATA_5_Pin LCD_DATA_6_Pin LCD_DATA_7_Pin */
  GPIO_InitStruct.Pin = LCD_DATA_8_Pin|LCD_DATA_9_Pin|LCD_DATA_10_Pin|LCD_DATA_11_Pin
                          |LCD_DATA_12_Pin|LCD_DATA_13_Pin|LCD_DATA_14_Pin|LCD_DATA_15_Pin
                          |LCD_DATA_0_Pin|LCD_DATA_1_Pin|LCD_DATA_2_Pin|LCD_DATA_3_Pin
                          |LCD_DATA_4_Pin|LCD_DATA_5_Pin|LCD_DATA_6_Pin|LCD_DATA_7_Pin;
  GPIO_InitStruct.Mode = GPIO_MODE_OUTPUT_PP;
  GPIO_InitStruct.Pull = GPIO_NOPULL;
  GPIO_InitStruct.Speed = GPIO_SPEED_FREQ_LOW;
  HAL_GPIO_Init(GPIOD, &GPIO_InitStruct);

  /*Configure GPIO pin : ESP_IRQ_Pin */
  GPIO_InitStruct.Pin = ESP_IRQ_Pin;
  GPIO_InitStruct.Mode = GPIO_MODE_IT_RISING;
  GPIO_InitStruct.Pull = GPIO_NOPULL;
  HAL_GPIO_Init(ESP_IRQ_GPIO_Port, &GPIO_InitStruct);

  /*Configure GPIO pin : ESP_RESET_Pin */
  GPIO_InitStruct.Pin = ESP_RESET_Pin;
  GPIO_InitStruct.Mode = GPIO_MODE_OUTPUT_PP;
  GPIO_InitStruct.Pull = GPIO_NOPULL;
  GPIO_InitStruct.Speed = GPIO_SPEED_FREQ_LOW;
  HAL_GPIO_Init(ESP_RESET_GPIO_Port, &GPIO_InitStruct);

  /*Configure GPIO pins : LCD_CS_Pin LCD_RS_Pin */
  GPIO_InitStruct.Pin = LCD_CS_Pin|LCD_RS_Pin;
  GPIO_InitStruct.Mode = GPIO_MODE_OUTPUT_PP;
  GPIO_InitStruct.Pull = GPIO_NOPULL;
  GPIO_InitStruct.Speed = GPIO_SPEED_FREQ_LOW;
  HAL_GPIO_Init(GPIOB, &GPIO_InitStruct);

}

/* USER CODE BEGIN 4 */
void LED_HB_Task(void *argument)
{
  /* Infinite loop */
  for(;;)
  {
    osDelay(1);
  }
}

/* USER CODE END 4 */

void StartDefaultTask(void *argument)
{
  /* init code for LWIP */
  MX_LWIP_Init();
  for(;;)
  {
    osDelay(1);
  }
}

void Error_Handler(void)
{
  __disable_irq();
  while (1)
  {
  }
}
